AUTOSAR XML (schema 00051)
package /SwComponentTypes
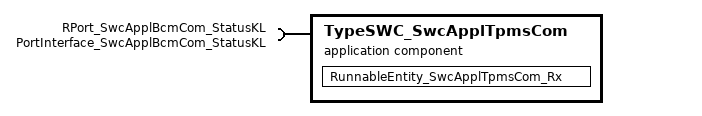
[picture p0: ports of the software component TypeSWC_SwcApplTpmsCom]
  application sw component type TypeSWC_SwcApplTpmsCom
    require port RPort_SwcApplBcmCom_StatusKL: required-interface=PortInterface_SwcApplBcmCom_StatusKL
    behavior InternalBehavior_SwcApplTpmsCom_Rx: data-type-mapping=MappingSetTypeData_SwcApplBcmCom
      timing event TimingEvent_SwcApplTpmsCom_Rx: start-on-event=RunnableEntity_SwcApplTpmsCom_Rx
      runnable RunnableEntity_SwcApplTpmsCom_Rx: symbol=FuncRunnableEntity_SwcApplTpmsCom
        data-read-access:
          access DataReadAccess_DataElement_eKL30R: accessed-variable=RPort_SwcApplBcmCom_StatusKL.DataElement_eKL30R
